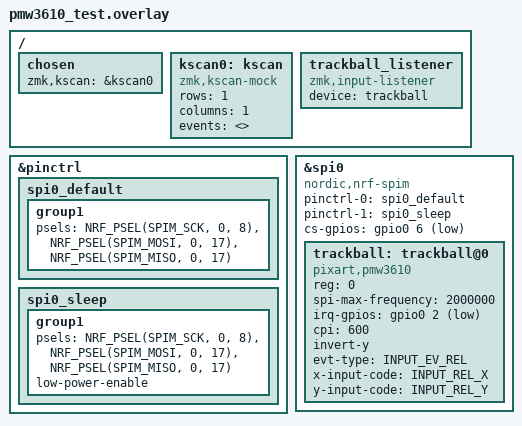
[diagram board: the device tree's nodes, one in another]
#include <zephyr/dt-bindings/gpio/gpio.h>
#include <zephyr/dt-bindings/input/input-event-codes.h>
#include <dt-bindings/pinctrl/nrf-pinctrl.h>

/ {
    chosen {
        zmk,kscan = &kscan0;
    };

    // ZMK needs a keymap/scan device. This placeholder uses no GPIOs and
    // generates no key events, so the sensor can be tested on its own.
    kscan0: kscan {
        compatible = "zmk,kscan-mock";
        rows = <1>;
        columns = <1>;
        events = <>;
    };

    trackball_listener {
        compatible = "zmk,input-listener";
        device = <&trackball>;
    };
};

&pinctrl {
    spi0_default: spi0_default {
        group1 {
            // PMW3610 has one bidirectional SDIO wire: both functions
            // deliberately use P0.17. Do not wire a separate MOSI pin.
            psels = <NRF_PSEL(SPIM_SCK, 0, 8)>,
                    <NRF_PSEL(SPIM_MOSI, 0, 17)>,
                    <NRF_PSEL(SPIM_MISO, 0, 17)>;
        };
    };

    spi0_sleep: spi0_sleep {
        group1 {
            psels = <NRF_PSEL(SPIM_SCK, 0, 8)>,
                    <NRF_PSEL(SPIM_MOSI, 0, 17)>,
                    <NRF_PSEL(SPIM_MISO, 0, 17)>;
            low-power-enable;
        };
    };
};

&spi0 {
    compatible = "nordic,nrf-spim";
    status = "okay";
    pinctrl-0 = <&spi0_default>;
    pinctrl-1 = <&spi0_sleep>;
    pinctrl-names = "default", "sleep";
    cs-gpios = <&gpio0 6 GPIO_ACTIVE_LOW>;

    trackball: trackball@0 {
        compatible = "pixart,pmw3610";
        status = "okay";
        reg = <0>;
        spi-max-frequency = <2000000>;
        irq-gpios = <&gpio0 2 (GPIO_ACTIVE_LOW | GPIO_PULL_UP)>;
        cpi = <600>;
        invert-y;
        evt-type = <INPUT_EV_REL>;
        x-input-code = <INPUT_REL_X>;
        y-input-code = <INPUT_REL_Y>;
    };
};
